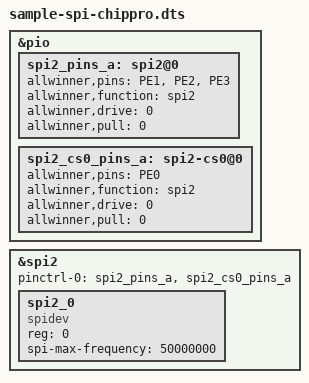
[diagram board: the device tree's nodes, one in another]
/*
 * Copyright 2017 NextThing Co
 *
 * Andrew Langley <andrew@nextthing.co>
 *
 * This file is dual-licensed: you can use it either under the terms
 * of the GPL or the X11 license, at your option. Note that this dual
 * licensing only applies to this file, and not this project as a
 * whole.
 *
 *  a) This file is free software; you can redistribute it and/or
 *     modify it under the terms of the GNU General Public License as
 *     published by the Free Software Foundation; either version 2 of the
 *     License, or (at your option) any later version.
 *
 *     This file is distributed in the hope that it will be useful,
 *     but WITHOUT ANY WARRANTY; without even the implied warranty of
 *     MERCHANTABILITY or FITNESS FOR A PARTICULAR PURPOSE.  See the
 *     GNU General Public License for more details.
 *
 * Or, alternatively,
 *
 *  b) Permission is hereby granted, free of charge, to any person
 *     obtaining a copy of this software and associated documentation
 *     files (the "Software"), to deal in the Software without
 *     restriction, including without limitation the rights to use,
 *     copy, modify, merge, publish, distribute, sublicense, and/or
 *     sell copies of the Software, and to permit persons to whom the
 *     Software is furnished to do so, subject to the following
 *     conditions:
 *
 *     The above copyright notice and this permission notice shall be
 *     included in all copies or substantial portions of the Software.
 *
 *     THE SOFTWARE IS PROVIDED "AS IS", WITHOUT WARRANTY OF ANY KIND,
 *     EXPRESS OR IMPLIED, INCLUDING BUT NOT LIMITED TO THE WARRANTIES
 *     OF MERCHANTABILITY, FITNESS FOR A PARTICULAR PURPOSE AND
 *     NONINFRINGEMENT. IN NO EVENT SHALL THE AUTHORS OR COPYRIGHT
 *     HOLDERS BE LIABLE FOR ANY CLAIM, DAMAGES OR OTHER LIABILITY,
 *     WHETHER IN AN ACTION OF CONTRACT, TORT OR OTHERWISE, ARISING
 *     FROM, OUT OF OR IN CONNECTION WITH THE SOFTWARE OR THE USE OR
 *     OTHER DEALINGS IN THE SOFTWARE.
 */

/dts-v1/;
/plugin/;

/ {
	/*
	 * Enable our SPI device, with an spidev device connected
	 * to it
	*/

	fragment@0 {
		target = <&pio>;

		__overlay__ {
			spi2_pins_a: spi2@0 {
				allwinner,pins = "PE1", "PE2", "PE3";
				allwinner,function = "spi2";
				allwinner,drive = <0>;
				allwinner,pull = <0>;
			};

			spi2_cs0_pins_a: spi2-cs0@0 {
				allwinner,pins = "PE0";
				allwinner,function = "spi2";
				allwinner,drive = <0>;
				allwinner,pull = <0>;
			};
		};
	};

	fragment@1 {
		target=<&spi2>;

		__overlay__ {
				status = "okay";
				pinctrl-names = "default";
				pinctrl-0 = <&spi2_pins_a>, <&spi2_cs0_pins_a>;

				spi2_0 {
					#address-cells = <1>;
					#size-cells = <0>;

					compatible = "spidev";

					reg = <0>;
					spi-max-frequency = <50000000>;
			};
		};
	};
};
